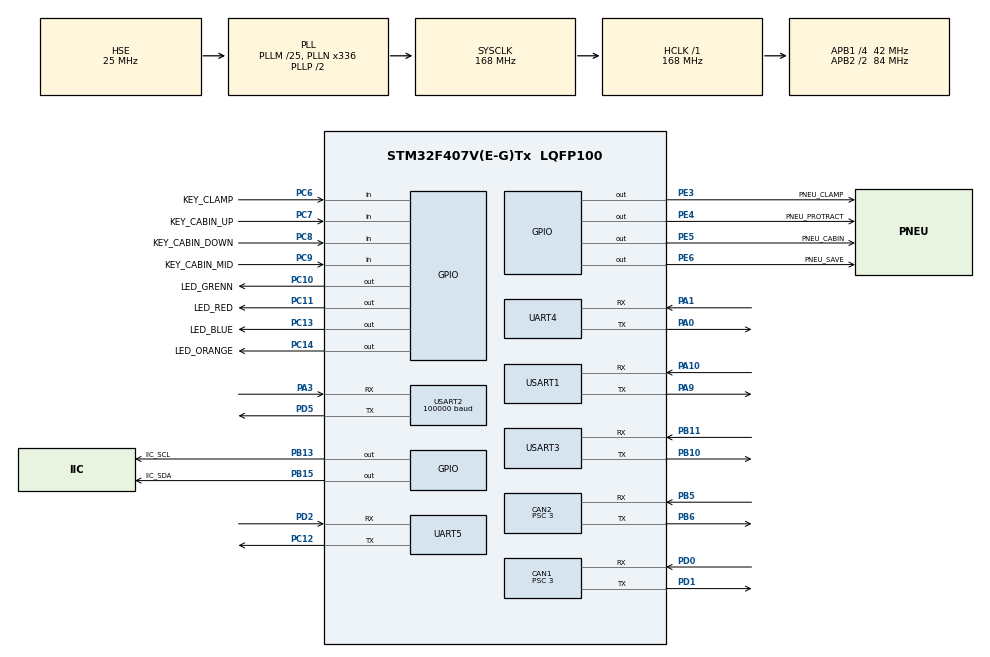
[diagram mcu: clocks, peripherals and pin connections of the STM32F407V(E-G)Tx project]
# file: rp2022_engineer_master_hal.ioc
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CAN1.ABOM=ENABLE
CAN1.AWUM=ENABLE
CAN1.BS1=CAN_BS1_9TQ
CAN1.BS2=CAN_BS2_4TQ
CAN1.CalculateBaudRate=1000000
CAN1.CalculateTimeBit=999.99
CAN1.CalculateTimeQuantum=71.42857142857143
CAN1.NART=DISABLE
CAN1.Prescaler=3
CAN1.TXFP=ENABLE
CAN2.ABOM=ENABLE
CAN2.AWUM=ENABLE
CAN2.BS1=CAN_BS1_9TQ
CAN2.BS2=CAN_BS2_4TQ
CAN2.CalculateBaudRate=1000000
CAN2.CalculateTimeBit=999.99
CAN2.CalculateTimeQuantum=71.42857142857143
CAN2.NART=DISABLE
CAN2.Prescaler=3
CAN2.TXFP=ENABLE
Dma.Request0=USART2_RX
Dma.Request1=UART5_RX
Dma.Request2=UART5_TX
Dma.Request3=USART1_RX
Dma.Request4=UART4_RX
Dma.Request5=UART4_TX
Dma.UART4_RX.4.Direction=DMA_PERIPH_TO_MEMORY
Dma.UART4_RX.4.FIFOMode=DMA_FIFOMODE_DISABLE
Dma.UART4_RX.4.Instance=DMA1_Stream2
Dma.UART4_RX.4.MemDataAlignment=DMA_MDATAALIGN_BYTE
Dma.UART4_RX.4.MemInc=DMA_MINC_ENABLE
Dma.UART4_RX.4.Mode=DMA_CIRCULAR
Dma.UART4_RX.4.PeriphDataAlignment=DMA_PDATAALIGN_BYTE
Dma.UART4_RX.4.PeriphInc=DMA_PINC_DISABLE
Dma.UART4_RX.4.Priority=DMA_PRIORITY_LOW
Dma.UART4_TX.5.Direction=DMA_MEMORY_TO_PERIPH
Dma.UART4_TX.5.FIFOMode=DMA_FIFOMODE_DISABLE
Dma.UART4_TX.5.Instance=DMA1_Stream4
Dma.UART4_TX.5.MemDataAlignment=DMA_MDATAALIGN_BYTE
Dma.UART4_TX.5.MemInc=DMA_MINC_ENABLE
Dma.UART4_TX.5.Mode=DMA_NORMAL
Dma.UART4_TX.5.PeriphDataAlignment=DMA_PDATAALIGN_BYTE
Dma.UART4_TX.5.PeriphInc=DMA_PINC_DISABLE
Dma.UART4_TX.5.Priority=DMA_PRIORITY_LOW
Dma.UART5_RX.1.Direction=DMA_PERIPH_TO_MEMORY
Dma.UART5_RX.1.FIFOMode=DMA_FIFOMODE_DISABLE
Dma.UART5_RX.1.Instance=DMA1_Stream0
Dma.UART5_RX.1.MemDataAlignment=DMA_MDATAALIGN_BYTE
Dma.UART5_RX.1.MemInc=DMA_MINC_ENABLE
Dma.UART5_RX.1.Mode=DMA_CIRCULAR
Dma.UART5_RX.1.PeriphDataAlignment=DMA_PDATAALIGN_BYTE
Dma.UART5_RX.1.PeriphInc=DMA_PINC_DISABLE
Dma.UART5_RX.1.Priority=DMA_PRIORITY_LOW
Dma.UART5_TX.2.Direction=DMA_MEMORY_TO_PERIPH
Dma.UART5_TX.2.FIFOMode=DMA_FIFOMODE_DISABLE
Dma.UART5_TX.2.Instance=DMA1_Stream7
Dma.UART5_TX.2.MemDataAlignment=DMA_MDATAALIGN_BYTE
Dma.UART5_TX.2.MemInc=DMA_MINC_ENABLE
Dma.UART5_TX.2.Mode=DMA_CIRCULAR
Dma.UART5_TX.2.PeriphDataAlignment=DMA_PDATAALIGN_BYTE
Dma.UART5_TX.2.PeriphInc=DMA_PINC_DISABLE
Dma.UART5_TX.2.Priority=DMA_PRIORITY_LOW
Dma.USART1_RX.3.Direction=DMA_PERIPH_TO_MEMORY
Dma.USART1_RX.3.FIFOMode=DMA_FIFOMODE_DISABLE
Dma.USART1_RX.3.Instance=DMA2_Stream2
Dma.USART1_RX.3.MemDataAlignment=DMA_MDATAALIGN_BYTE
Dma.USART1_RX.3.MemInc=DMA_MINC_ENABLE
Dma.USART1_RX.3.Mode=DMA_CIRCULAR
Dma.USART1_RX.3.PeriphDataAlignment=DMA_PDATAALIGN_BYTE
Dma.USART1_RX.3.PeriphInc=DMA_PINC_DISABLE
Dma.USART1_RX.3.Priority=DMA_PRIORITY_LOW
Dma.USART2_RX.0.Direction=DMA_PERIPH_TO_MEMORY
Dma.USART2_RX.0.FIFOMode=DMA_FIFOMODE_DISABLE
Dma.USART2_RX.0.Instance=DMA1_Stream5
Dma.USART2_RX.0.MemDataAlignment=DMA_MDATAALIGN_BYTE
Dma.USART2_RX.0.MemInc=DMA_MINC_ENABLE
Dma.USART2_RX.0.Mode=DMA_CIRCULAR
Dma.USART2_RX.0.PeriphDataAlignment=DMA_PDATAALIGN_BYTE
Dma.USART2_RX.0.PeriphInc=DMA_PINC_DISABLE
Dma.USART2_RX.0.Priority=DMA_PRIORITY_LOW
FREERTOS.Tasks01=heatbeattask,3,128,Heart_Beat_Task,As weak,NULL,Dynamic,NULL,NULL;controltask,1,128,Control_Task,As weak,NULL,Dynamic,NULL,NULL;liftingtask,0,128,Lifting_Task,As weak,NULL,Dynamic,NULL,NULL;clamptask,0,128,Clamp_Task,As weak,NULL,Dynamic,NULL,NULL;groundtask,0,128,Ground_Task,As weak,NULL,Dynamic,NULL,NULL;tranlation,0,128,Tranlation_Task,As weak,NULL,Dynamic,NULL,NULL;minetask,0,128,Mine_Task,As weak,NULL,Dynamic,NULL,NULL;savetask,0,128,Save_Task,As weak,NULL,Dynamic,NULL,NULL;outputtask,0,128,Output_Task,As weak,NULL,Dynamic,NULL,NULL;autoprocess,1,128,Auto_Process_Task,As weak,NULL,Dynamic,NULL,NULL
IWDG.Prescaler=IWDG_PRESCALER_8
Mcu.Family=STM32F4
Mcu.Name=STM32F407V(E-G)Tx
Mcu.Package=LQFP100
NVIC.CAN1_RX0_IRQn=true\:5\:0\:false\:false\:true\:false\:true\:true
NVIC.CAN2_RX0_IRQn=true\:5\:0\:false\:false\:true\:false\:true\:true
NVIC.DMA1_Stream0_IRQn=true\:5\:0\:false\:false\:true\:true\:false\:true
NVIC.DMA1_Stream2_IRQn=true\:5\:0\:false\:false\:true\:true\:false\:true
NVIC.DMA1_Stream4_IRQn=true\:5\:0\:false\:false\:true\:true\:false\:true
NVIC.DMA1_Stream5_IRQn=true\:5\:0\:false\:false\:true\:true\:false\:true
NVIC.DMA1_Stream7_IRQn=true\:5\:0\:false\:false\:true\:true\:false\:true
NVIC.DMA2_Stream2_IRQn=true\:5\:0\:false\:false\:true\:true\:false\:true
NVIC.PriorityGroup=NVIC_PRIORITYGROUP_4
NVIC.TIM2_IRQn=true\:15\:0\:false\:false\:true\:false\:false\:true
NVIC.TimeBase=TIM2_IRQn
NVIC.TimeBaseIP=TIM2
NVIC.UART4_IRQn=true\:5\:0\:false\:false\:true\:false\:true\:true
NVIC.UART5_IRQn=true\:5\:0\:false\:false\:true\:false\:true\:true
NVIC.USART1_IRQn=true\:5\:0\:false\:false\:true\:false\:true\:true
NVIC.USART2_IRQn=true\:5\:0\:false\:false\:true\:false\:true\:true
PA0-WKUP.Mode=Asynchronous
PA0-WKUP.Signal=UART4_TX
PA1.Mode=Asynchronous
PA1.Signal=UART4_RX
PA10.Mode=Asynchronous
PA10.Signal=USART1_RX
PA3.Mode=Asynchronous
PA3.Signal=USART2_RX
PA9.Mode=Asynchronous
PA9.Signal=USART1_TX
PB10.Mode=Asynchronous
PB10.Signal=USART3_TX
PB11.Mode=Asynchronous
PB11.Signal=USART3_RX
PB13.GPIO_Label=IIC_SCL
PB13.GPIO_Speed=GPIO_SPEED_FREQ_VERY_HIGH
PB13.Signal=GPIO_Output
PB15.GPIO_Label=IIC_SDA
PB15.GPIO_Speed=GPIO_SPEED_FREQ_VERY_HIGH
PB15.Signal=GPIO_Output
PB5.Mode=CAN_Activate
PB5.Signal=CAN2_RX
PB6.Mode=CAN_Activate
PB6.Signal=CAN2_TX
PC10.GPIO_Label=LED_GRENN
PC10.GPIO_Speed=GPIO_SPEED_FREQ_HIGH
PC10.Signal=GPIO_Output
PC11.GPIO_Label=LED_RED
PC11.GPIO_Speed=GPIO_SPEED_FREQ_HIGH
PC11.Signal=GPIO_Output
PC12.Mode=Asynchronous
PC12.Signal=UART5_TX
PC13-ANTI_TAMP.GPIO_Label=LED_BLUE
PC13-ANTI_TAMP.GPIO_Speed=GPIO_SPEED_FREQ_LOW
PC13-ANTI_TAMP.Signal=GPIO_Output
PC14-OSC32_IN.GPIO_Label=LED_ORANGE
PC14-OSC32_IN.Signal=GPIO_Output
PC6.GPIO_Label=KEY_CLAMP
PC6.GPIO_PuPd=GPIO_NOPULL
PC6.Signal=GPIO_Input
PC7.GPIO_Label=KEY_CABIN_UP
PC7.GPIO_PuPd=GPIO_NOPULL
PC7.Signal=GPIO_Input
PC8.GPIO_Label=KEY_CABIN_DOWN
PC8.GPIO_PuPd=GPIO_NOPULL
PC8.Signal=GPIO_Input
PC9.GPIO_Label=KEY_CABIN_MID
PC9.GPIO_PuPd=GPIO_NOPULL
PC9.Signal=GPIO_Input
PD0.Mode=CAN_Activate
PD0.Signal=CAN1_RX
PD1.Mode=CAN_Activate
PD1.Signal=CAN1_TX
PD2.Mode=Asynchronous
PD2.Signal=UART5_RX
PD5.Mode=Asynchronous
PD5.Signal=USART2_TX
PE3.GPIO_Label=PNEU_CLAMP
PE3.GPIO_Speed=GPIO_SPEED_FREQ_HIGH
PE3.PinState=GPIO_PIN_RESET
PE3.Signal=GPIO_Output
PE4.GPIO_Label=PNEU_PROTRACT
PE4.GPIO_Speed=GPIO_SPEED_FREQ_HIGH
PE4.Signal=GPIO_Output
PE5.GPIO_Label=PNEU_CABIN
PE5.GPIO_Speed=GPIO_SPEED_FREQ_HIGH
PE5.Signal=GPIO_Output
PE6.GPIO_Label=PNEU_SAVE
PE6.GPIO_Speed=GPIO_SPEED_FREQ_HIGH
PE6.Signal=GPIO_Output
PH0-OSC_IN.Mode=HSE-External-Oscillator
PH0-OSC_IN.Signal=RCC_OSC_IN
PH1-OSC_OUT.Mode=HSE-External-Oscillator
PH1-OSC_OUT.Signal=RCC_OSC_OUT
ProjectManager.HeapSize=0x200
ProjectManager.StackSize=0x400
ProjectManager.TargetToolchain=MDK-ARM V5.27
RCC.48MHZClocksFreq_Value=84000000
RCC.AHBFreq_Value=168000000
RCC.APB1CLKDivider=RCC_HCLK_DIV4
RCC.APB1Freq_Value=42000000
RCC.APB1TimFreq_Value=84000000
RCC.APB2CLKDivider=RCC_HCLK_DIV2
RCC.APB2Freq_Value=84000000
RCC.APB2TimFreq_Value=168000000
RCC.CortexFreq_Value=168000000
RCC.HCLKFreq_Value=168000000
RCC.HSE_VALUE=25000000
RCC.HSI_VALUE=16000000
RCC.LSE_VALUE=32768
RCC.PLLM=25
RCC.PLLN=336
RCC.PLLSourceVirtual=RCC_PLLSOURCE_HSE
RCC.SYSCLKFreq_VALUE=168000000
RCC.SYSCLKSource=RCC_SYSCLKSOURCE_PLLCLK
RCC.VCOOutputFreq_Value=336000000
UART4.VirtualMode=Asynchronous
UART5.VirtualMode=Asynchronous
USART1.VirtualMode=VM_ASYNC
USART2.BaudRate=100000
USART2.VirtualMode=VM_ASYNC
USART3.VirtualMode=VM_ASYNC
VP_FREERTOS_VS_CMSIS_V1.Mode=CMSIS_V1
VP_IWDG_VS_IWDG.Mode=IWDG_Activate
VP_SYS_VS_tim2.Mode=TIM2
board=custom

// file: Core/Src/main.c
/* USER CODE BEGIN Header */
/**
  ******************************************************************************
  * @file           : main.c
  * @brief          : Main program body
  ******************************************************************************
  * @attention
  *
  * <h2><center>&copy; Copyright (c) 2021 STMicroelectronics.
  * All rights reserved.</center></h2>
  *
  * This software component is licensed by ST under Ultimate Liberty license
  * SLA0044, the "License"; You may not use this file except in compliance with
  * the License. You may obtain a copy of the License at:
  *                             www.st.com/SLA0044
  *
  ******************************************************************************
  */
/* USER CODE END Header */
#include "main.h"
#include "cmsis_os.h"
#include "can.h"
#include "dma.h"
#include "iwdg.h"
#include "usart.h"
#include "gpio.h"

/* USER CODE BEGIN Includes */
#include "drv_can.h"
#include "drv_uart.h"
/* USER CODE END Includes */

void SystemClock_Config(void);
void MX_FREERTOS_Init(void);

int main(void)
{

  /* MCU Configuration--------------------------------------------------------*/

  /* Reset of all peripherals, Initializes the Flash interface and the Systick. */
  HAL_Init();

  /* Configure the system clock */
  SystemClock_Config();

  /* Initialize all configured peripherals */
  MX_GPIO_Init();
  MX_DMA_Init();
  MX_CAN1_Init();
  MX_CAN2_Init();
  MX_UART5_Init();
  MX_USART2_UART_Init();
  MX_USART1_UART_Init();
  MX_UART4_Init();
  MX_USART3_UART_Init();
//  MX_IWDG_Init();
  /* USER CODE BEGIN 2 */
	CAN_Init();
	USART2_Init();
	USART4_Init();
  /* USER CODE END 2 */

  /* Call init function for freertos objects (in freertos.c) */
  MX_FREERTOS_Init();
  /* Start scheduler */
  osKernelStart();

  /* We should never get here as control is now taken by the scheduler */
  /* Infinite loop */
  while (1)
  {

  }
}

void SystemClock_Config(void)
{
  RCC_OscInitTypeDef RCC_OscInitStruct = {0};
  RCC_ClkInitTypeDef RCC_ClkInitStruct = {0};

  /** Configure the main internal regulator output voltage
  */
  __HAL_RCC_PWR_CLK_ENABLE();
  __HAL_PWR_VOLTAGESCALING_CONFIG(PWR_REGULATOR_VOLTAGE_SCALE1);
  /** Initializes the RCC Oscillators according to the specified parameters
  * in the RCC_OscInitTypeDef structure.
  */
  RCC_OscInitStruct.OscillatorType = RCC_OSCILLATORTYPE_LSI|RCC_OSCILLATORTYPE_HSE;
  RCC_OscInitStruct.HSEState = RCC_HSE_ON;
  RCC_OscInitStruct.LSIState = RCC_LSI_ON;
  RCC_OscInitStruct.PLL.PLLState = RCC_PLL_ON;
  RCC_OscInitStruct.PLL.PLLSource = RCC_PLLSOURCE_HSE;
  RCC_OscInitStruct.PLL.PLLM = 25;
  RCC_OscInitStruct.PLL.PLLN = 336;
  RCC_OscInitStruct.PLL.PLLP = RCC_PLLP_DIV2;
  RCC_OscInitStruct.PLL.PLLQ = 4;
  if (HAL_RCC_OscConfig(&RCC_OscInitStruct) != HAL_OK)
  {
    Error_Handler();
  }
  /** Initializes the CPU, AHB and APB buses clocks
  */
  RCC_ClkInitStruct.ClockType = RCC_CLOCKTYPE_HCLK|RCC_CLOCKTYPE_SYSCLK
                              |RCC_CLOCKTYPE_PCLK1|RCC_CLOCKTYPE_PCLK2;
  RCC_ClkInitStruct.SYSCLKSource = RCC_SYSCLKSOURCE_PLLCLK;
  RCC_ClkInitStruct.AHBCLKDivider = RCC_SYSCLK_DIV1;
  RCC_ClkInitStruct.APB1CLKDivider = RCC_HCLK_DIV4;
  RCC_ClkInitStruct.APB2CLKDivider = RCC_HCLK_DIV2;

  if (HAL_RCC_ClockConfig(&RCC_ClkInitStruct, FLASH_LATENCY_5) != HAL_OK)
  {
    Error_Handler();
  }
}

void HAL_TIM_PeriodElapsedCallback(TIM_HandleTypeDef *htim)
{
  if (htim->Instance == TIM2) {
    HAL_IncTick();
  }
}

void Error_Handler(void)
{
  __disable_irq();
  while (1)
  {
  }
}

/************************ (C) COPYRIGHT STMicroelectronics *****END OF FILE****/

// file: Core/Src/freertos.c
/* USER CODE BEGIN Header */
/**
  ******************************************************************************
  * File Name          : freertos.c
  * Description        : Code for freertos applications
  ******************************************************************************
  * @attention
  *
  * <h2><center>&copy; Copyright (c) 2021 STMicroelectronics.
  * All rights reserved.</center></h2>
  *
  * This software component is licensed by ST under Ultimate Liberty license
  * SLA0044, the "License"; You may not use this file except in compliance with
  * the License. You may obtain a copy of the License at:
  *                             www.st.com/SLA0044
  *
  ******************************************************************************
  */
/* USER CODE END Header */

#include "FreeRTOS.h"
#include "task.h"
#include "main.h"
#include "cmsis_os.h"

osThreadId heatbeattaskHandle;
osThreadId controltaskHandle;
osThreadId liftingtaskHandle;
osThreadId clamptaskHandle;
osThreadId groundtaskHandle;
osThreadId tranlationHandle;
osThreadId minetaskHandle;
osThreadId savetaskHandle;
osThreadId outputtaskHandle;
osThreadId autoprocessHandle;

void Heart_Beat_Task(void const * argument);
void Control_Task(void const * argument);
void Lifting_Task(void const * argument);
void Clamp_Task(void const * argument);
void Ground_Task(void const * argument);
void Tranlation_Task(void const * argument);
void Mine_Task(void const * argument);
void Save_Task(void const * argument);
void Output_Task(void const * argument);
void Auto_Process_Task(void const * argument);

void MX_FREERTOS_Init(void); /* (MISRA C 2004 rule 8.1) */

/* GetIdleTaskMemory prototype (linked to static allocation support) */
void vApplicationGetIdleTaskMemory( StaticTask_t **ppxIdleTaskTCBBuffer, StackType_t **ppxIdleTaskStackBuffer, uint32_t *pulIdleTaskStackSize );

/* USER CODE BEGIN GET_IDLE_TASK_MEMORY */
static StaticTask_t xIdleTaskTCBBuffer;
static StackType_t xIdleStack[configMINIMAL_STACK_SIZE];

void vApplicationGetIdleTaskMemory( StaticTask_t **ppxIdleTaskTCBBuffer, StackType_t **ppxIdleTaskStackBuffer, uint32_t *pulIdleTaskStackSize )
{
  *ppxIdleTaskTCBBuffer = &xIdleTaskTCBBuffer;
  *ppxIdleTaskStackBuffer = &xIdleStack[0];
  *pulIdleTaskStackSize = configMINIMAL_STACK_SIZE;
  /* place for user code */
}
/* USER CODE END GET_IDLE_TASK_MEMORY */

void MX_FREERTOS_Init(void) {

  /* Create the thread(s) */
  /* definition and creation of heatbeattask */
  osThreadDef(heatbeattask, Heart_Beat_Task, osPriorityRealtime, 0, 128);
  heatbeattaskHandle = osThreadCreate(osThread(heatbeattask), NULL);

  /* definition and creation of controltask */
  osThreadDef(controltask, Control_Task, osPriorityAboveNormal, 0, 128);
  controltaskHandle = osThreadCreate(osThread(controltask), NULL);

  /* definition and creation of liftingtask */
  osThreadDef(liftingtask, Lifting_Task, osPriorityNormal, 0, 128);
  liftingtaskHandle = osThreadCreate(osThread(liftingtask), NULL);

  /* definition and creation of clamptask */
  osThreadDef(clamptask, Clamp_Task, osPriorityNormal, 0, 128);
  clamptaskHandle = osThreadCreate(osThread(clamptask), NULL);

  /* definition and creation of groundtask */
  osThreadDef(groundtask, Ground_Task, osPriorityNormal, 0, 128);
  groundtaskHandle = osThreadCreate(osThread(groundtask), NULL);

  /* definition and creation of tranlation */
  osThreadDef(tranlation, Tranlation_Task, osPriorityNormal, 0, 128);
  tranlationHandle = osThreadCreate(osThread(tranlation), NULL);

  /* definition and creation of minetask */
  osThreadDef(minetask, Mine_Task, osPriorityNormal, 0, 128);
  minetaskHandle = osThreadCreate(osThread(minetask), NULL);

  /* definition and creation of savetask */
  osThreadDef(savetask, Save_Task, osPriorityNormal, 0, 128);
  savetaskHandle = osThreadCreate(osThread(savetask), NULL);

  /* definition and creation of outputtask */
  osThreadDef(outputtask, Output_Task, osPriorityNormal, 0, 128);
  outputtaskHandle = osThreadCreate(osThread(outputtask), NULL);

  /* definition and creation of autoprocess */
  osThreadDef(autoprocess, Auto_Process_Task, osPriorityAboveNormal, 0, 128);
  autoprocessHandle = osThreadCreate(osThread(autoprocess), NULL);

}

__weak void Heart_Beat_Task(void const * argument)
{
  for(;;)
  {
    osDelay(1);
  }
}

__weak void Control_Task(void const * argument)
{
  for(;;)
  {
    osDelay(1);
  }
}

__weak void Lifting_Task(void const * argument)
{
  for(;;)
  {
    osDelay(1);
  }
}

__weak void Clamp_Task(void const * argument)
{
  for(;;)
  {
    osDelay(1);
  }
}

__weak void Ground_Task(void const * argument)
{
  for(;;)
  {
    osDelay(1);
  }
}

__weak void Tranlation_Task(void const * argument)
{
  for(;;)
  {
    osDelay(1);
  }
}

__weak void Mine_Task(void const * argument)
{
  for(;;)
  {
    osDelay(1);
  }
}

__weak void Save_Task(void const * argument)
{
  for(;;)
  {
    osDelay(1);
  }
}

__weak void Output_Task(void const * argument)
{
  for(;;)
  {
    osDelay(1);
  }
}

__weak void Auto_Process_Task(void const * argument)
{
  for(;;)
  {
    osDelay(1);
  }
}

/************************ (C) COPYRIGHT STMicroelectronics *****END OF FILE****/
